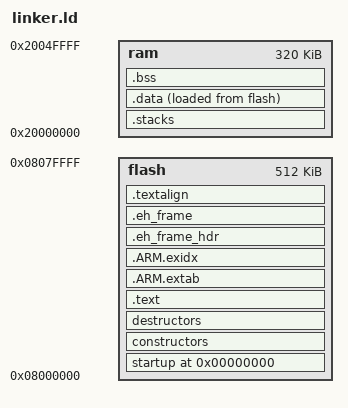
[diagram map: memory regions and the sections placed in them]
/******************************************************************************
 ________  ________  ___  ________  ________  ___  _________  ________      
|\   __  \|\   __  \|\  \|\   ____\|\   ____\|\  \|\___   ___\\   ____\     
\ \  \|\ /\ \  \|\  \ \  \ \  \___|\ \  \___|\ \  \|___ \  \_\ \  \___|_    
 \ \   __  \ \   _  _\ \  \ \_____  \ \  \    \ \  \   \ \  \ \ \_____  \   
  \ \  \|\  \ \  \\  \\ \  \|____|\  \ \  \____\ \  \   \ \  \ \|____|\  \  
   \ \_______\ \__\\ _\\ \__\____\_\  \ \_______\ \__\   \ \__\  ____\_\  \ 
    \|_______|\|__|\|__|\|__|\_________\|_______|\|__|    \|__| |\_________\
                            \|_________|                        \|_________|
                            
MIT License

Copyright (c) 2021 Mike Sharkey

Permission is hereby granted, free of charge, to any person obtaining a copy
of this software and associated documentation files (the "Software"), to deal
in the Software without restriction, including without limitation the rights
to use, copy, modify, merge, publish, distribute, sublicense, and/or sell
copies of the Software, and to permit persons to whom the Software is
furnished to do so, subject to the following conditions:

The above copyright notice and this permission notice shall be included in all
copies or substantial portions of the Software.

THE SOFTWARE IS PROVIDED "AS IS", WITHOUT WARRANTY OF ANY KIND, EXPRESS OR
IMPLIED, INCLUDING BUT NOT LIMITED TO THE WARRANTIES OF MERCHANTABILITY,
FITNESS FOR A PARTICULAR PURPOSE AND NONINFRINGEMENT. IN NO EVENT SHALL THE
AUTHORS OR COPYRIGHT HOLDERS BE LIABLE FOR ANY CLAIM, DAMAGES OR OTHER
LIABILITY, WHETHER IN AN ACTION OF CONTRACT, TORT OR OTHERWISE, ARISING FROM,
OUT OF OR IN CONNECTION WITH THE SOFTWARE OR THE USE OR OTHER DEALINGS IN THE
SOFTWARE.

******************************************************************************/
__main_stack_size__     = 0x0600;
__process_stack_size__  = 0x0600;

MEMORY
{
    flash : org = 0x08000000, len = 512k
    ram   : org = 0x20000000, len = 320k
}

__ram_start__           = ORIGIN(ram);
__ram_size__            = LENGTH(ram);
__ram_end__             = __ram_start__ + __ram_size__;

SECTIONS
{
    . = 0;
    _text = .;

    startup : ALIGN(16) SUBALIGN(16)
    {
        KEEP(*(.vectors))
    } > flash

    constructors : ALIGN(4) SUBALIGN(4)
    {
        PROVIDE(__init_array_start = .);
        KEEP(*(SORT(.init_array.*)))
        KEEP(*(.init_array))
        PROVIDE(__init_array_end = .);
    } > flash

    destructors : ALIGN(4) SUBALIGN(4)
    {
        PROVIDE(__fini_array_start = .);
        KEEP(*(.fini_array))
        KEEP(*(SORT(.fini_array.*)))
        PROVIDE(__fini_array_end = .);
    } > flash

    .text : ALIGN(16) SUBALIGN(16)
    {
        *(.text.startup.*)
        *(.init)
        *(.text)
        *(.text.*)
        *(.rodata)
        *(.rodata.*)
        *(.glue_7t)
        *(.glue_7)
        *(.gcc*)
    } > flash

    .ARM.extab :
    {
        *(.ARM.extab* .gnu.linkonce.armextab.*)
    } > flash

    .ARM.exidx : {
        PROVIDE(__exidx_start = .);
        *(.ARM.exidx* .gnu.linkonce.armexidx.*)
        PROVIDE(__exidx_end = .);
     } > flash

    .eh_frame_hdr :
    {
        *(.eh_frame_hdr)
    } > flash

    .eh_frame : ONLY_IF_RO
    {
        *(.eh_frame)
    } > flash

    .textalign : ONLY_IF_RO
    {
        . = ALIGN(8);
    } > flash

    _etext = .;

    .stacks :
    {
        . = ALIGN(8);
        __main_stack_base__ = .;
        . += __main_stack_size__;
        . = ALIGN(8);
        __main_stack_end__ = .;
        _sstack = .;
        __main_thread_stack_base__ = .;
        . += __process_stack_size__;
        . = ALIGN(8);
        _estack = .;
        __main_thread_stack_end__ = .;
    } > ram

    .data :
    {
        . = ALIGN(4);
        PROVIDE(_sdata = .);
        *(.data)
        . = ALIGN(4);
        *(.data.*)
        . = ALIGN(4);
        *(.ramtext)
        . = ALIGN(4);
        PROVIDE(_edata = .);
    } > ram AT > flash

    .bss :
    {
        . = ALIGN(4);
        PROVIDE(_sbss = .);
        *(.bss)
        . = ALIGN(4);
        *(.bss.*)
        . = ALIGN(4);
        *(COMMON)
        . = ALIGN(4);
        PROVIDE(_ebss = .);
    } > ram
}

PROVIDE(end = .);
_end            = .;

__heap_start__   = _end;
__heap_end__    = __ram_end__;
